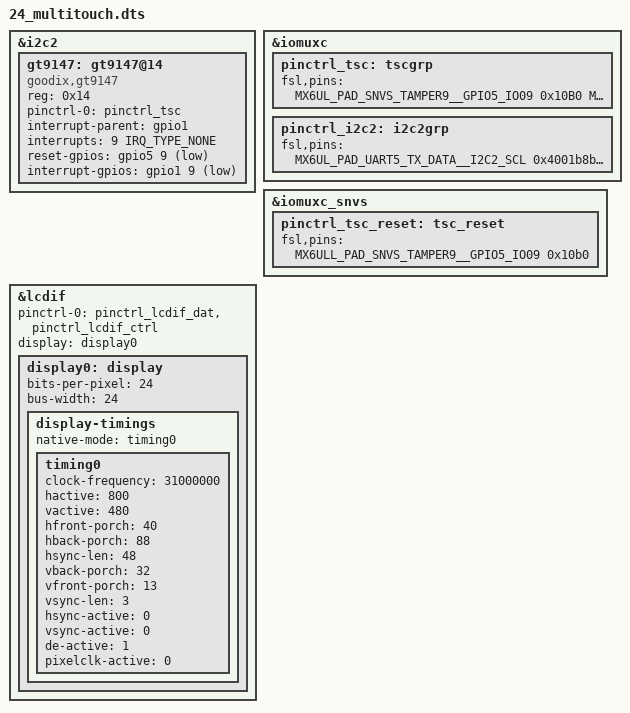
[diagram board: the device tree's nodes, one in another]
&i2c2 {
   	gt9147: gt9147@14 {
		compatible = "goodix,gt9147", "goodix,gt9xx";
		reg = <0x14>;
		pinctrl-names = "default";
		pinctrl-0 = <&pinctrl_tsc>;
		interrupt-parent = <&gpio1>;
		interrupts = <9 IRQ_TYPE_NONE>;
		reset-gpios = <&gpio5 9 GPIO_ACTIVE_LOW>;
		interrupt-gpios = <&gpio1 9 GPIO_ACTIVE_LOW>;
		status = "okay";
	};
};

&iomuxc {
        /*you tsc INT*/
		pinctrl_tsc: tscgrp {
			fsl,pins = <
				/* 4.3 寸 RGB 屏幕,GT9147 */
				MX6UL_PAD_SNVS_TAMPER9__GPIO5_IO09 		0x10B0 /* TSC_RST */
				MX6UL_PAD_GPIO1_IO09__GPIO1_IO09		0x10B0 /* TSC_INT */
			>;
		};

        pinctrl_i2c2: i2c2grp {
			fsl,pins = <
				MX6UL_PAD_UART5_TX_DATA__I2C2_SCL 0x4001b8b0
				MX6UL_PAD_UART5_RX_DATA__I2C2_SDA 0x4001b8b0
			>;
		}; 
};

&iomuxc_snvs {
        /*you MT RST*/
		pinctrl_tsc_reset: tsc_reset {
			fsl,pins = <
				MX6ULL_PAD_SNVS_TAMPER9__GPIO5_IO09		0x10b0
			>;
		};
};

&lcdif {
	pinctrl-names = "default";
	pinctrl-0 = <&pinctrl_lcdif_dat
		     &pinctrl_lcdif_ctrl>;
	display = <&display0>;
	status = "okay";

	display0: display {
		bits-per-pixel = <24>;
		bus-width = <24>;

		display-timings {
			native-mode = <&timing0>;
			timing0: timing0 {
			clock-frequency = <31000000>;
			hactive = <800>;
			vactive = <480>;
			hfront-porch = <40>;
			hback-porch = <88>;
			hsync-len = <48>;
			vback-porch = <32>;
			vfront-porch = <13>;
			vsync-len = <3>;

			hsync-active = <0>;
			vsync-active = <0>;
			de-active = <1>;
			pixelclk-active = <0>;
			};
		};
	};
};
